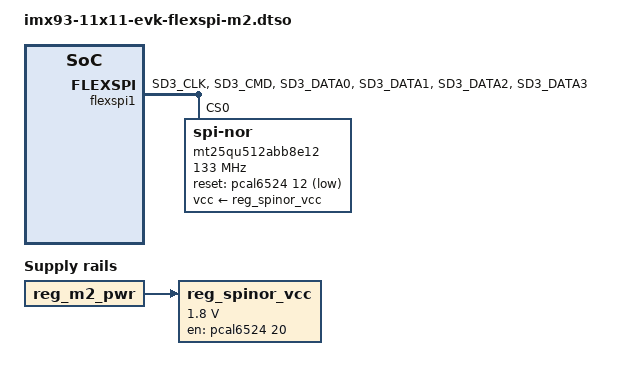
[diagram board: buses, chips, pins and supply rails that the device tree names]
// SPDX-License-Identifier: (GPL-2.0+ OR MIT)
/*
 * Copyright 2024 NXP
 */

#include <dt-bindings/gpio/gpio.h>
#include <dt-bindings/interrupt-controller/irq.h>
#include "imx93-pinfunc.h"

/dts-v1/;
/plugin/;

&{/} {
	reg_spinor_vcc: regulator-spinor {
		compatible = "regulator-fixed";
		regulator-name = "SPINOR";
		regulator-min-microvolt = <1800000>;
		regulator-max-microvolt = <1800000>;
		vin-supply = <&reg_m2_pwr>;
		gpio = <&pcal6524 20 GPIO_ACTIVE_HIGH>;
		startup-delay-us = <2000>;
		enable-active-high;
	};
};

&usdhc3 {
	status = "disabled";
};

&flexspi1 {
	#address-cells = <1>;
	#size-cells = <0>;
	pinctrl-names = "default";
	pinctrl-0 = <&pinctrl_flexspi1>;
	status = "okay";

	mt25qu512abb8e12: flash@0 {
		compatible = "jedec,spi-nor";
		reg = <0>;
		vcc-supply = <&reg_spinor_vcc>;
		reset-gpios = <&pcal6524 12 GPIO_ACTIVE_LOW>;
		spi-max-frequency = <133000000>;
		spi-tx-bus-width = <4>;
		spi-rx-bus-width = <4>;
	};
};

&iomuxc {
	pinctrl_flexspi1: flexspi1grp {
		fsl,pins = <
			MX93_PAD_SD3_CLK__FLEXSPI1_A_SCLK	0x3fe
			MX93_PAD_SD3_CMD__FLEXSPI1_A_SS0_B	0x3fe
			MX93_PAD_SD3_DATA0__FLEXSPI1_A_DATA00	0x3fe
			MX93_PAD_SD3_DATA1__FLEXSPI1_A_DATA01	0x3fe
			MX93_PAD_SD3_DATA2__FLEXSPI1_A_DATA02	0x3fe
			MX93_PAD_SD3_DATA3__FLEXSPI1_A_DATA03	0x3fe
		>;
	};
};
